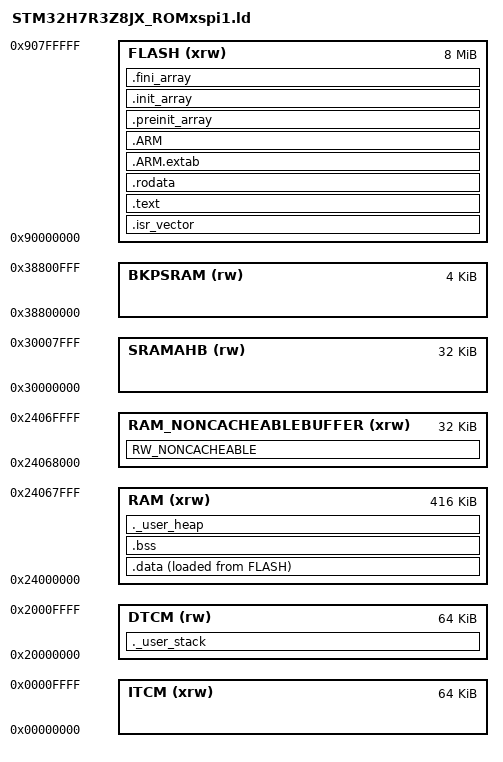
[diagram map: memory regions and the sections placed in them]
/*
******************************************************************************
**
** @file        : LinkerScript.ld
**
** @author      : STM32CubeIDE
**
**  Abstract    : Linker script for STM32H7Rxx Device
**                      8 MBytes XSPI1 XiP (PY25Q64HA)
**                      456KBytes RAM
**
**                Set heap size, stack size and stack location according
**                to application requirements.
**
**                Set memory bank area and size if external memory is used
**
**  Target      : STMicroelectronics STM32
**
**  Distribution: The file is distributed as is, without any warranty
**                of any kind.
**
******************************************************************************
** @attention
**
** Copyright (c) 2026 STMicroelectronics.
** All rights reserved.
**
** This software is licensed under terms that can be found in the LICENSE file
** in the root directory of this software component.
** If no LICENSE file comes with this software, it is provided AS-IS.
**
******************************************************************************
*/

/* Entry Point */
ENTRY(Reset_Handler)

/* Highest address of the user mode stack */
_estack = ORIGIN(DTCM) + LENGTH(DTCM); /* end of "DTCM" Ram type memory */

_Min_Heap_Size = 0x4000; /* USBPD stack + CDC CLI (malloc'd PD DMA buffers live here) */
/* 8 KB, raised from 4 KB.  The EPR path is the deepest call chain in this
 * firmware: USBPD_PE_StateMachine_SNK -> EPRMode_Enter -> DPM callbacks,
 * on top of which the application logger uses a 256-byte stack buffer per
 * APP_LOG_Printf.  DTCM is 64 KB and only the stack lives there, so the
 * extra 4 KB is free.  A stack overflow here lands in a while(1) fault
 * handler, which on the bench is indistinguishable from a bricked board. */
_Min_Stack_Size = 0x2000;

__FLASH_BEGIN  = 0x90000000;
__FLASH_SIZE   = 0x00800000; /* PY25Q64HA: 64 Mbit = 8 MByte */


/* AXI SRAM split.  The CubeMX memory template for this device budgets
 * 456 KiB of AXI SRAM (see STM32H7R3Z8JX__default_MMT_TEMPLATE.ld:
 * RAM = 455K + 1K non-cacheable), i.e. 0x24000000..0x24072000.
 *
 * The cacheable part holds .data/.bss and the newlib heap; the tail holds
 * every buffer a DMA engine can touch (USB OTG_HS CDC RX/TX, the log TX
 * buffer and the TRACER_EMB context), which main.c maps as an MPU
 * non-cacheable region.
 *
 * The window MUST be aligned to its own size: an ARMv7 MPU region is
 * (size)-aligned and the hardware ignores the low address bits.  The window
 * therefore starts at 0x24068000 and is 32 KiB, not 16 KiB at 0x2406E000
 * (which is only 8 KiB aligned and would silently become 0x2406C000).
 *
 *   0x24000000 .. 0x24068000   416 KiB  cacheable    (__RAM_SIZE)
 *   0x24068000 .. 0x24070000    32 KiB  non-cacheable (DMA / USB / TRACER)
 *   total 0x70000 = 448 KiB, inside the 456 KiB AXI SRAM budget. */
__RAM_BEGIN    = 0x24000000;
__RAM_SIZE     = 0x68000; /* cacheable AXI SRAM; DMA window begins at 0x24068000 */
__RAM_NONCACHEABLEBUFFER_SIZE = 0x8000; /* 32 KiB DMA/USB CDC/TRACER, 32 KiB aligned */

/* Memories definition */
MEMORY
{
  RAM       (xrw) : ORIGIN = __RAM_BEGIN,    LENGTH = __RAM_SIZE
  RAM_NONCACHEABLEBUFFER (xrw) : ORIGIN = __RAM_BEGIN + __RAM_SIZE,  LENGTH = __RAM_NONCACHEABLEBUFFER_SIZE

  ITCM      (xrw) : ORIGIN = 0x00000000,    LENGTH = 0x00010000
  DTCM       (rw) : ORIGIN = 0x20000000,    LENGTH = 0x00010000
  SRAMAHB   (rw)  : ORIGIN = 0x30000000,  LENGTH = 0x00008000
  BKPSRAM   (rw)  : ORIGIN = 0x38800000,  LENGTH = 0x00001000

  FLASH     (xrw) : ORIGIN = __FLASH_BEGIN, LENGTH = __FLASH_SIZE
}

/* Keep the linker layout and MPU_Config() in Appli/Core/Src/main.c in step.
 *
 * An ARMv7 MPU region is aligned to its own size - the hardware ignores the
 * low address bits of the base - and main.c programs the region that makes
 * this window non-cacheable as MPU_REGION_SIZE_32KB at 0x24068000.  If either
 * symbol below changes without a matching edit there, the MPU would describe a
 * different piece of AXI SRAM than the one holding the DMA buffers, and the
 * USB OTG_HS DMA and the CM7 D-cache would disagree.  Fail the link instead. */
ASSERT(__RAM_NONCACHEABLEBUFFER_SIZE == 0x8000,
       "non-cacheable window is not 32 KiB: update MPU region 4 in Appli/Core/Src/main.c")
ASSERT(__RAM_SIZE % __RAM_NONCACHEABLEBUFFER_SIZE == 0,
       "non-cacheable window base is not aligned to its own size: MPU would round it down")

/* Sections */
SECTIONS
{
  /* The startup code into "FLASH" Rom type memory */
  .isr_vector :
  {
    . = ALIGN(4);
    KEEP(*(.isr_vector)) /* Startup code */
    . = ALIGN(4);
  } >FLASH

  /* The program code and other data into "FLASH" Rom type memory */
  .text :
  {
    . = ALIGN(4);
    *(.text)           /* .text sections (code) */
    *(.text*)          /* .text* sections (code) */
    *(.glue_7)         /* glue arm to thumb code */
    *(.glue_7t)        /* glue thumb to arm code */
    *(.eh_frame)

    KEEP (*(.init))
    KEEP (*(.fini))

    . = ALIGN(4);
    _etext = .;        /* define a global symbols at end of code */
  } >FLASH

  /* Constant data into "FLASH" Rom type memory */
  .rodata :
  {
    . = ALIGN(4);
    *(.rodata)         /* .rodata sections (constants, strings, etc.) */
    *(.rodata*)        /* .rodata* sections (constants, strings, etc.) */
    . = ALIGN(4);
  } >FLASH

  .ARM.extab (READONLY) : /* The READONLY keyword is only supported in GCC11 and later, remove it if using GCC10 or earlier. */
  {
    . = ALIGN(4);
    *(.ARM.extab* .gnu.linkonce.armextab.*)
    . = ALIGN(4);
  } >FLASH
  .ARM (READONLY) : /* The READONLY keyword is only supported in GCC11 and later, remove it if using GCC10 or earlier. */
  {
    . = ALIGN(4);
    __exidx_start = .;
    *(.ARM.exidx*)
    __exidx_end = .;
    . = ALIGN(4);
  } >FLASH

  .preinit_array (READONLY) : /* The READONLY keyword is only supported in GCC11 and later, remove it if using GCC10 or earlier. */
  {
    . = ALIGN(4);
    PROVIDE_HIDDEN (__preinit_array_start = .);
    KEEP (*(.preinit_array*))
    PROVIDE_HIDDEN (__preinit_array_end = .);
    . = ALIGN(4);
  } >FLASH

  .init_array (READONLY) : /* The READONLY keyword is only supported in GCC11 and later, remove it if using GCC10 or earlier. */
  {
    . = ALIGN(4);
    PROVIDE_HIDDEN (__init_array_start = .);
    KEEP (*(SORT(.init_array.*)))
    KEEP (*(.init_array*))
    PROVIDE_HIDDEN (__init_array_end = .);
    . = ALIGN(4);
  } >FLASH

  .fini_array (READONLY) : /* The READONLY keyword is only supported in GCC11 and later, remove it if using GCC10 or earlier. */
  {
    . = ALIGN(4);
    PROVIDE_HIDDEN (__fini_array_start = .);
    KEEP (*(SORT(.fini_array.*)))
    KEEP (*(.fini_array*))
    PROVIDE_HIDDEN (__fini_array_end = .);
    . = ALIGN(4);
  } >FLASH

  /* Used by the startup to initialize data */
  _sidata = LOADADDR(.data);

  /* Initialized data sections into "RAM" Ram type memory */
  .data :
  {
    . = ALIGN(4);
    _sdata = .;        /* create a global symbol at data start */
    *(.data)           /* .data sections */
    *(.data*)          /* .data* sections */
    *(.RamFunc)        /* .RamFunc sections */
    *(.RamFunc*)       /* .RamFunc* sections */

    . = ALIGN(4);
    _edata = .;        /* define a global symbol at data end */

  } >RAM AT> FLASH

  /* Uninitialized data section into "RAM" Ram type memory */
  . = ALIGN(4);
  .bss :
  {
    /* This is used by the startup in order to initialize the .bss section */
    _sbss = .;         /* define a global symbol at bss start */
    __bss_start__ = _sbss;
    *(.bss)
    *(.bss*)
    *(COMMON)

    . = ALIGN(4);
    _ebss = .;         /* define a global symbol at bss end */
    __bss_end__ = _ebss;
  } >RAM

  RW_NONCACHEABLE (NOLOAD):
  {
    __NONCACHEABLEBUFFER_BEGIN = .;/* create symbol for start of section */
    KEEP(*(noncacheable_buffer))
    __NONCACHEABLEBUFFER_END = .;  /* create symbol for start of section */
  } > RAM_NONCACHEABLEBUFFER

  /* newlib heap.  MUST live in DMA-accessible AXI SRAM, NOT DTCM: the USBPD
     stack allocates its RX/TX DMA buffers with malloc(), and on STM32H7R3
     only the CPU and HPDMA can reach the TCM memories (AN6062) - the UCPD's
     GPDMA1 (channels 0/1) cannot.  A DTCM heap makes every malloc'd DMA
     buffer unreachable, so PD messages are never received while CC
     attach/detach (which needs no DMA) still works. */
  ._user_heap :
  {
    . = ALIGN(8);
    PROVIDE ( end = . );
    PROVIDE ( _end = . );
    . = . + _Min_Heap_Size;
    . = ALIGN(8);
  } >RAM

  /* MSP stack stays in fast, CPU-only DTCM (it is never touched by DMA). */
  ._user_stack :
  {
    . = ALIGN(8);
    . = . + _Min_Stack_Size;
    . = ALIGN(8);
  } >DTCM

  /* Upper bound of the newlib heap: start of the non-cacheable window. */
  _Heap_Limit = __RAM_BEGIN + __RAM_SIZE;

  /* Remove information from the compiler libraries */
  /DISCARD/ :
  {
    libc.a ( * )
    libm.a ( * )
    libgcc.a ( * )
  }

  .ARM.attributes 0 : { *(.ARM.attributes) }
}
